# main_pll_mmr_MAIN_PLL_MMR_CFG_00680000h register map
Vendor: Texas Instruments
Peripheral module from a debugger description file (folder am62D).
Registers are 32-bit, read-write, reset values left out (the file's numbers can be read two ways) unless marked. A register's access mark holds for its fields unless they carry their own. Offsets are as the file gives them; lines under a group give offsets from that group; [hi:lo] are bit positions; {n}, {i} and the like mark numbered series; 'fields as' and 'values as' point back to an identical list; <NAME> marks a mode.

## main_pll_mmr_CFG
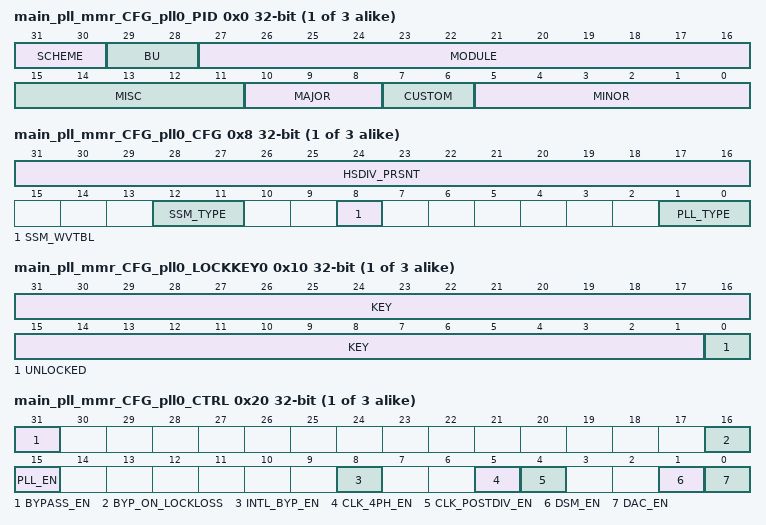
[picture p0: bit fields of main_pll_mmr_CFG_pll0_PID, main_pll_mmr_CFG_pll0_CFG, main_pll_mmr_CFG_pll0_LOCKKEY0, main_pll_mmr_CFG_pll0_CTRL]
{0x0+0x1000*i} main_pll_mmr_CFG_pll{i}_PID ro (i=0..2)
  [31:30] SCHEME — PID follows new scheme Reset Source: sys_por_arst_rst_n
  [29:28] BU — Business Unit - Processors Reset Source: sys_por_arst_rst_n
  [27:16] MODULE — Module functional identifier Reset Source: sys_por_arst_rst_n
  [15:11] MISC — Misc revision number Reset Source: sys_por_arst_rst_n
  [10:8] MAJOR — Major revision number Reset Source: sys_por_arst_rst_n
  [7:6] CUSTOM — custom revision number Reset Source: sys_por_arst_rst_n
  [5:0] MINOR — Minor revision number Reset Source: sys_por_arst_rst_n
{0x8+0x1000*i} main_pll_mmr_CFG_pll{i}_CFG ro (i=0..2)
  [31:16] HSDIV_PRSNT — High Speed Divider Presence Each bit Indicates the presence of High Speed dividers 0-15. By definition HSDIV[4:0] are connected the PLL FOUTVCO output clock and HSDIV[15:5] areconnected to the PLL FOUTPOSTDIV output clock Reset Source: sys_por_arst_rst_n
  [12:11] SSM_TYPE — Spread spectrum module presence Field values (Others are reserved): 2'b00 - SSM is not present 2'b01 - SSM is present 2'b10 - Reserved 2'b11 - Reserved Reset Source: sys_por_arst_rst_n
  [8] SSM_WVTBL — Spread spectrum wave table presence 1'b0 - SSM Wave table is not present 1'b1 - SSM Wave table is present Reset Source: sys_por_arst_rst_n
  [1:0] PLL_TYPE — Indicates PLL type Field values (Others are reserved): 2'b00 - Fractional PLL 2'b01 - FractionalF PLL 2'b10 - De-Skew PLL Reset Source: sys_por_arst_rst_n
{0x10+0x1000*i} main_pll_mmr_CFG_pll{i}_LOCKKEY0 access per field (i=0..2)
  [31:1] KEY rw — Write the kick0 unlock value followed by the kick1 unlock value to unlock the write-protectedPartition{i} registers Reset Source: srst_n
  [0] UNLOCKED ro — Unlock status. When set, indicates that the proper unlock sequence has been performed and the partition isunlocked for Writing. Reset Source: srst_n
{0x14+0x1000*i} main_pll_mmr_CFG_pll{i}_LOCKKEY1 (i=0..2)
  [31:0] LOCKKEY1_VAL — Write the kick1 unlock value after the kick0 unlock value to unlock the write-protected Partition{i}registers Reset Source: srst_n
{0x20+0x1000*i} main_pll_mmr_CFG_pll{i}_CTRL (i=0..2)
  [31] BYPASS_EN — Bypass enable. This controls the glitch-free bypass mux. The bypass_en bit should be set prior tomaking any changes to the PLL settings. 1'b0 - Synchronously select PLL and associated HSDIV clock outputs 1'b1 - Synchronously select the reference clock for all PLL and HSDIV clock outputs Reset Source: sys_por_arst_rst_n
  [16] BYP_ON_LOCKLOSS — Bypass on loss of PLL lock. This bit controls the PLL bypass mux to automatically switch theclock source to the reference clock when the PLL losses lock. 1'b0 - Do not automatically switch to ref clock source on PLL lock loss 1'b1 - Switch to ref clock source when PLL losses lock Reset Source: sys_por_arst_rst_n
  [15] PLL_EN — PLL enable 1'b0 - PLL is disabled 1'b1 - PLL is enabled Reset Source: sys_por_arst_rst_n
  [8] INTL_BYP_EN — PLL internal bypass enable. This is an asynchronous mux which can produce glitches on the outputclocks during switching. 1'b0 - Output clocks are derived from the VCO clock 1'b1 - Output clocks are derived from the FREF reference clock Reset Source: sys_por_arst_rst_n
  [5] CLK_4PH_EN — Enable 4-phase clock generator. This bit is ignored if clk_postdiv_en=0 1'b0 - 4-phase dividers disabled. FOUT1PHx and FOUTn clocks are held low. 1'b1 - 4-phase dividers enabled. FOUT1PH0/90/180/270 and FOUT2, FOUT3, FOUT4 clocks are enabled. Reset Source: sys_por_arst_rst_n
  [4] CLK_POSTDIV_EN — Post divide CLK enable 1'b0 - Post divide powered down. FOUTPOSTDIV and all auxiliary PLL clocks (4-ohase andsynchronous divided clocks) are held low 1'b1 - Post divide enabled. FOUTPOSTDIV, 4-phase and synchronous clocks are enabled. Reset Source: sys_por_arst_rst_n
  [1] DSM_EN — Delta-Sigma modulator enable 1'b0 - Delta-Sigma modulator is disabled (use integer divide mode) 1'b1 - Delta-Sigma modulator is enabled (use fractional divide mode) Reset Source: sys_por_arst_rst_n
  [0] DAC_EN — Enable fractional noise canceling DACThis bit has no function (DAC is always disabled) in integer divide mode (when dsm_en=0) 1'b0 - Fractional NC DAC is disabled (for Test modes only) 1'b1 - Fractional NC DAC is enabled (ignored in integer divide mode) Reset Source: sys_por_arst_rst_n
{0x24+0x1000*i} main_pll_mmr_CFG_pll{i}_STAT ro (i=0..2)
  [0] LOCK — PLL lock status. Software should wait for lock to be asserted before clearing thePLL_CTRL_bypass_en bit 1'b0 - PLL is not locked 1'b1 - PLL is locked Reset Source: sys_por_arst_rst_n
{0x30+0x1000*i} main_pll_mmr_CFG_pll{i}_FREQ_CTRL0 (i=0..2)
  [11:0] FB_DIV_INT — PLL feedback divider (integer portion) In Integer mode values of 16 - 3200 (dec) are supported. In Fractional mode values of 20 to 320 are supported. 12'h010 - Divide by 16 12'h011 - Divide by 17 : 12'h140 - Divide by 320 : 12'hC80 - Divide by 3200 12'hC81 - 12'hFFF - Not supported Reset Source: sys_por_arst_rst_n
{0x34+0x1000*i} main_pll_mmr_CFG_pll{i}_FREQ_CTRL1 (i=0..2)
  [23:0] FB_DIV_FRAC — PLL feedback divider (fractional portion) Supports values of 0 to 0.999999940395. The total feedback divide value is (fb_div_int + fb_div_frac / (2^24)) 24'h000000 - 0 24'h000001 - .000000059605 (1/(2^24)) 24'h000002 - .000000119209 (2/(2^24)) : 24'h800000 - .500000000000 : 24'hFFFFFF - .999999940395 (1677215/(2^24)) Reset Source: sys_por_arst_rst_n
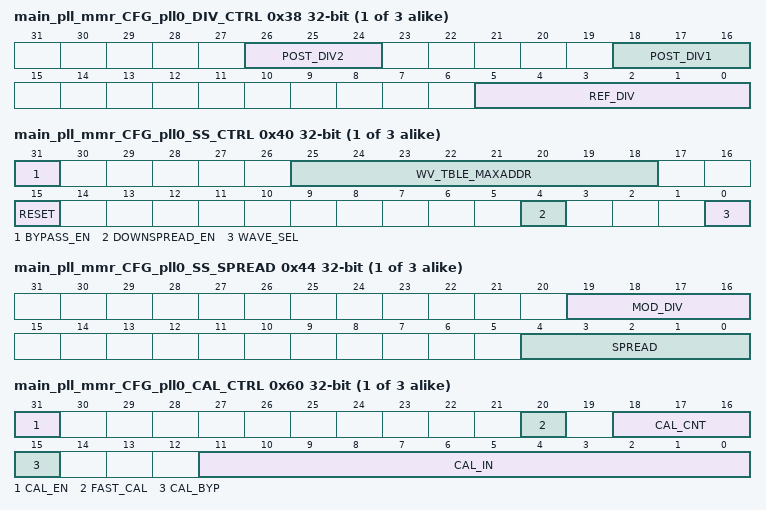
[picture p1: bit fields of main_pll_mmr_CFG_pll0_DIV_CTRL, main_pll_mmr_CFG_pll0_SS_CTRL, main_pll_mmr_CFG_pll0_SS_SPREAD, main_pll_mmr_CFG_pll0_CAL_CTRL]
{0x38+0x1000*i} main_pll_mmr_CFG_pll{i}_DIV_CTRL (i=0..2)
  [26:24] POST_DIV2 — Secondary post divider. Supports values of 1-7 Reset Source: sys_por_arst_rst_n
  [18:16] POST_DIV1 — Primary post divider. To ensure correct operation, post_div1 must always be programmed to avalue equal to or greater that post_div2. Supports values of 1-7i Field values (Others are reserved): 3'b000 - Reserved (do not use) 3'b001 - Divide by 1 3'b010 - Divide by 2 3'b011 - Divide by 3 3'b100 - Divide by 4 3'b101 - Divide by 5 3'b110 - Divide by 6 3'b111 - Divide by 7 Reset Source: sys_por_arst_rst_n
  [5:0] REF_DIV — Reference clock pre-divider. Supports values of 1-63 6'b000000 - Reserved /(do not use/) 6'b000001 - Divide by 1 6'b000010 - Divide by 2 : 6'b111111 - Divide by 63 Reset Source: sys_por_arst_rst_n
{0x40+0x1000*i} main_pll_mmr_CFG_pll{i}_SS_CTRL (i=0..2)
  [31] BYPASS_EN — Bypass the SS modulator.1'b0 - Spread spectrum modulation is enabled1'b1 - SSMOD is bypassed. No modulation of PLL frequency Reset Source: sys_por_arst_rst_n
  [25:18] WV_TBLE_MAXADDR — Wave table max address. Indicates the maximum number of address bits used to access the external wave table. These bits are not used if PLL_CFG_ssm_wvtbl = 0 Reset Source: sys_por_arst_rst_n
  [15] RESET — SSM reset. When set to 1 the SSM modulator is in reset Reset Source: sys_por_arst_rst_n
  [4] DOWNSPREAD_EN — Selects center spread or down spread clock variance1'b0 - Center spread1'b1 - Down spread Reset Source: sys_por_arst_rst_n
  [0] WAVE_SEL — Wave pattern select External wave table should only be selected if PLL_CFG_ssm_wvtbl = 1Field values (Others are reserved):1'b0 - Use 128 point triangle wave table1'b1 - Use external wave table Reset Source: sys_por_arst_rst_n
{0x44+0x1000*i} main_pll_mmr_CFG_pll{i}_SS_SPREAD (i=0..2)
  [19:16] MOD_DIV — Input clock divider. This divider sets the modulation frequency. Supports divide values of 1-15 Reset Source: sys_por_arst_rst_n
  [4:0] SPREAD — Sets the spread modulation depth. The depth is spread*0.1%5'b00000 - Reserved (don't use)5'b00001 - 0.1%5'b00010 - 0.2%:5'b10000 - 1.6%:5'b11111 - 3.1% Reset Source: sys_por_arst_rst_n
{0x60+0x1000*i} main_pll_mmr_CFG_pll{i}_CAL_CTRL (i=0..2)
  [31] CAL_EN — Calibration enable to actively adjust for input skew 1'b0 - Disabled. Static phase offset determined by analog matching only 1'b1 - Enabled. Static phase offset adjusted by phase sensing at input Reset Source: sys_por_arst_rst_n
  [20] FAST_CAL — Fast calibration enabled 1'b0 - Normal operation 1'b1 - Used for initial calibration if initial value is not already known Reset Source: sys_por_arst_rst_n
  [18:16] CAL_CNT — Calibration loop programmable counter. Selects the number of PFD edges to wait after eachcalibration step defined by 2**cal_cnt Reset Source: sys_por_arst_rst_n
  [15] CAL_BYP — Calibration bypass 1'b0 - Use the calibration output to set the phase correction 1'b1 - Use the cal_in input value to set the phase correction Reset Source: sys_por_arst_rst_n
  [11:0] CAL_IN — Calibration input When cal_byp is 1'b0, this represents the initial condition for calibration. When cal_byp is 1'b1, this is the override value for calibration. Value is a signed integer with positive values delaying the faster path reset and negative valuesdelaying the slower path reset. Reset Source: sys_por_arst_rst_n
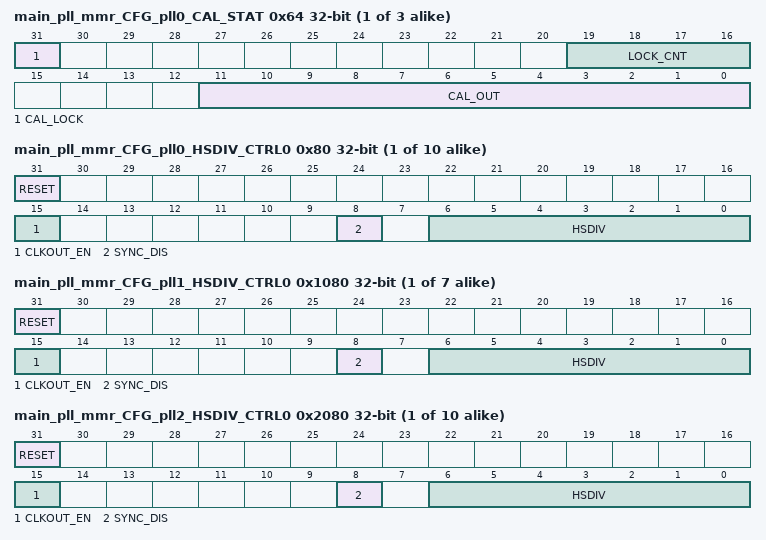
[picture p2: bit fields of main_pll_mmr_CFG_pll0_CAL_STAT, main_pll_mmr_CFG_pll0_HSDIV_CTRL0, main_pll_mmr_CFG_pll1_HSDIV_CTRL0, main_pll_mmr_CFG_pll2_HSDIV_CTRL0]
{0x64+0x1000*i} main_pll_mmr_CFG_pll{i}_CAL_STAT ro (i=0..2)
  [31] CAL_LOCK — Reserved for future use Reset Source: sys_por_arst_rst_n
  [19:16] LOCK_CNT — Reserved for future use Reset Source: sys_por_arst_rst_n
  [11:0] CAL_OUT — Output of the calibration block if cal_byp = 1'b0. If cal_byp = 1'b1 it is a buffer version of cal_in[11:0]. Can be used to read the phase calibration state to for later use as an override value to bypass skew calibration Reset Source: sys_por_arst_rst_n
{0x80+4i} main_pll_mmr_CFG_pll0_HSDIV_CTRL{i} (i=0..9)
  [31] RESET — SSM reset. When set to 1 the SSM modulator is in resetl Reset Source: sys_por_arst_rst_n
  [15] CLKOUT_EN — CLKOUT1 enable1'b0 - Synchronously disable CLKOUT11'b1 - Synchronously enable CLKOUT1 Reset Source: sys_por_arst_rst_n
  [8] SYNC_DIS — Disable divider synchronization logic0 - Changes to DIV value synchronized to prevent glitches1 - Changes are asynchronous Reset Source: sys_por_arst_rst_n
  [6:0] HSDIV — CLKOUT0 divider value (HSDIV1+1)Allowed values are 0-127 Reset Source: sys_por_arst_rst_n
{0x1080+4i} main_pll_mmr_CFG_pll1_HSDIV_CTRL{i} (i=0..6)
  fields as main_pll_mmr_CFG_pll0_HSDIV_CTRL0
{0x2080+4i} main_pll_mmr_CFG_pll2_HSDIV_CTRL{i} (i=0..9)
  fields as main_pll_mmr_CFG_pll0_HSDIV_CTRL0
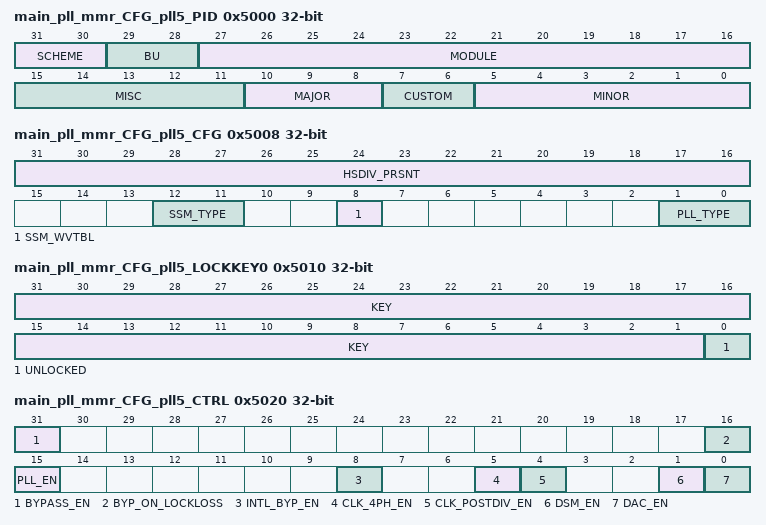
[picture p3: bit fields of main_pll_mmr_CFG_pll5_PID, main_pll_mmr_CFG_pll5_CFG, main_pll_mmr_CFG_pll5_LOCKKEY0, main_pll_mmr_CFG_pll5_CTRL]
0x5000 main_pll_mmr_CFG_pll5_PID ro
  fields as main_pll_mmr_CFG_pll0_PID
0x5008 main_pll_mmr_CFG_pll5_CFG ro
  fields as main_pll_mmr_CFG_pll0_CFG
0x5010 main_pll_mmr_CFG_pll5_LOCKKEY0 access per field
  [31:1] KEY rw — Write the kick0 unlock value followed by the kick1 unlock value to unlock the write-protectedPartition5 registers Reset Source: srst_n
  [0] UNLOCKED ro — Unlock status. When set, indicates that the proper unlock sequence has been performed and the partition isunlocked for Writing. Reset Source: srst_n
0x5014 main_pll_mmr_CFG_pll5_LOCKKEY1
  [31:0] LOCKKEY1_VAL — Write the kick1 unlock value after the kick0 unlock value to unlock the write-protected Partition5registers Reset Source: srst_n
0x5020 main_pll_mmr_CFG_pll5_CTRL
  fields as main_pll_mmr_CFG_pll0_CTRL
0x5024 main_pll_mmr_CFG_pll5_STAT ro
  fields as main_pll_mmr_CFG_pll0_STAT
0x5030 main_pll_mmr_CFG_pll5_FREQ_CTRL0
  fields as main_pll_mmr_CFG_pll0_FREQ_CTRL0
0x5034 main_pll_mmr_CFG_pll5_FREQ_CTRL1
  fields as main_pll_mmr_CFG_pll0_FREQ_CTRL1
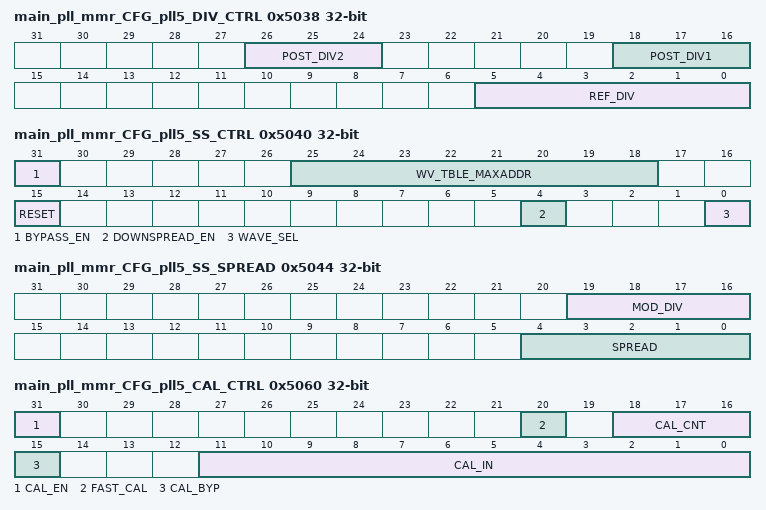
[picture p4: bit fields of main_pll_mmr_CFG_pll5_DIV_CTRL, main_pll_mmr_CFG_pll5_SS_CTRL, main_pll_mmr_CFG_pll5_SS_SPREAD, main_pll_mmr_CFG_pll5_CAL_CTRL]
0x5038 main_pll_mmr_CFG_pll5_DIV_CTRL
  fields as main_pll_mmr_CFG_pll0_DIV_CTRL
0x5040 main_pll_mmr_CFG_pll5_SS_CTRL
  fields as main_pll_mmr_CFG_pll0_SS_CTRL
0x5044 main_pll_mmr_CFG_pll5_SS_SPREAD
  fields as main_pll_mmr_CFG_pll0_SS_SPREAD
0x5060 main_pll_mmr_CFG_pll5_CAL_CTRL
  fields as main_pll_mmr_CFG_pll0_CAL_CTRL
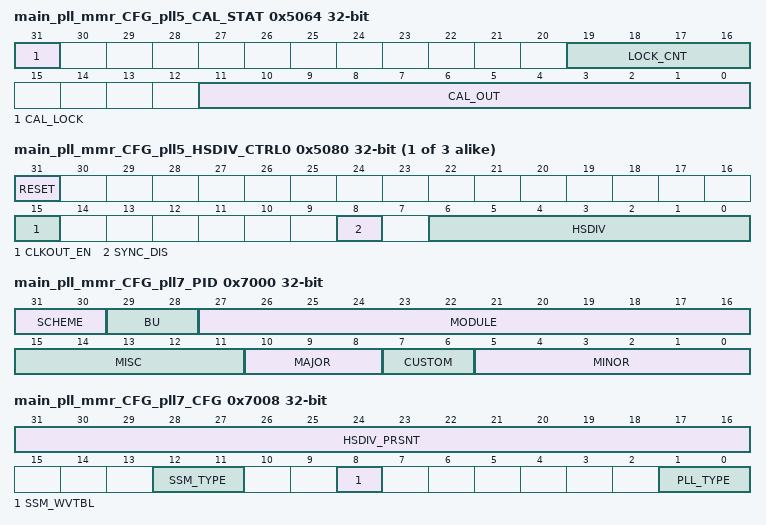
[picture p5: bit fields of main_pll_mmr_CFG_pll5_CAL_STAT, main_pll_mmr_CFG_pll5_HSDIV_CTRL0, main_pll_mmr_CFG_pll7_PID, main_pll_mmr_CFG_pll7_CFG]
0x5064 main_pll_mmr_CFG_pll5_CAL_STAT ro
  fields as main_pll_mmr_CFG_pll0_CAL_STAT
{0x5080+4i} main_pll_mmr_CFG_pll5_HSDIV_CTRL{i} (i=0..2)
  fields as main_pll_mmr_CFG_pll0_HSDIV_CTRL0
0x7000 main_pll_mmr_CFG_pll7_PID ro
  fields as main_pll_mmr_CFG_pll0_PID
0x7008 main_pll_mmr_CFG_pll7_CFG ro
  fields as main_pll_mmr_CFG_pll0_CFG
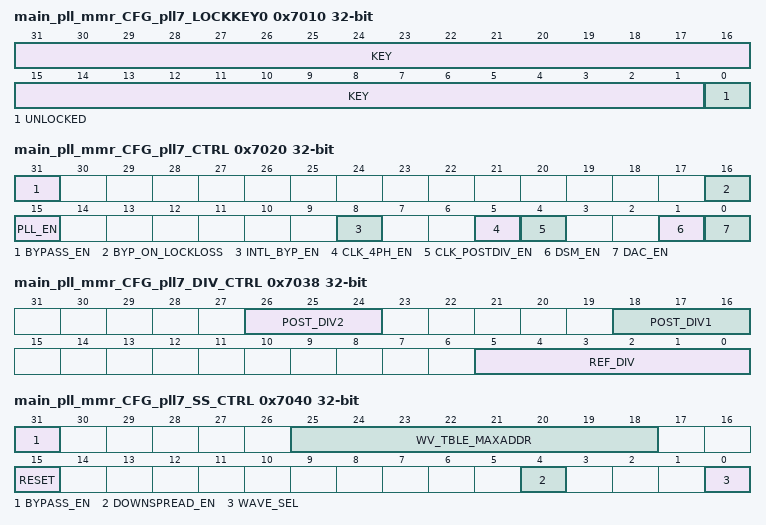
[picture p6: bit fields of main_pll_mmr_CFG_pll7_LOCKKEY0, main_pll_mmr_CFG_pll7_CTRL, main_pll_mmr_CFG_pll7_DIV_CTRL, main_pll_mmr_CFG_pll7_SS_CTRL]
0x7010 main_pll_mmr_CFG_pll7_LOCKKEY0 access per field
  [31:1] KEY rw — Write the kick0 unlock value followed by the kick1 unlock value to unlock the write-protectedPartition7 registers Reset Source: srst_n
  [0] UNLOCKED ro — Unlock status. When set, indicates that the proper unlock sequence has been performed and the partition isunlocked for Writing. Reset Source: srst_n
0x7014 main_pll_mmr_CFG_pll7_LOCKKEY1
  [31:0] LOCKKEY1_VAL — Write the kick1 unlock value after the kick0 unlock value to unlock the write-protected Partition7registers Reset Source: srst_n
0x7020 main_pll_mmr_CFG_pll7_CTRL
  fields as main_pll_mmr_CFG_pll0_CTRL
0x7024 main_pll_mmr_CFG_pll7_STAT ro
  fields as main_pll_mmr_CFG_pll0_STAT
0x7030 main_pll_mmr_CFG_pll7_FREQ_CTRL0
  fields as main_pll_mmr_CFG_pll0_FREQ_CTRL0
0x7034 main_pll_mmr_CFG_pll7_FREQ_CTRL1
  fields as main_pll_mmr_CFG_pll0_FREQ_CTRL1
0x7038 main_pll_mmr_CFG_pll7_DIV_CTRL
  fields as main_pll_mmr_CFG_pll0_DIV_CTRL
0x7040 main_pll_mmr_CFG_pll7_SS_CTRL
  fields as main_pll_mmr_CFG_pll0_SS_CTRL
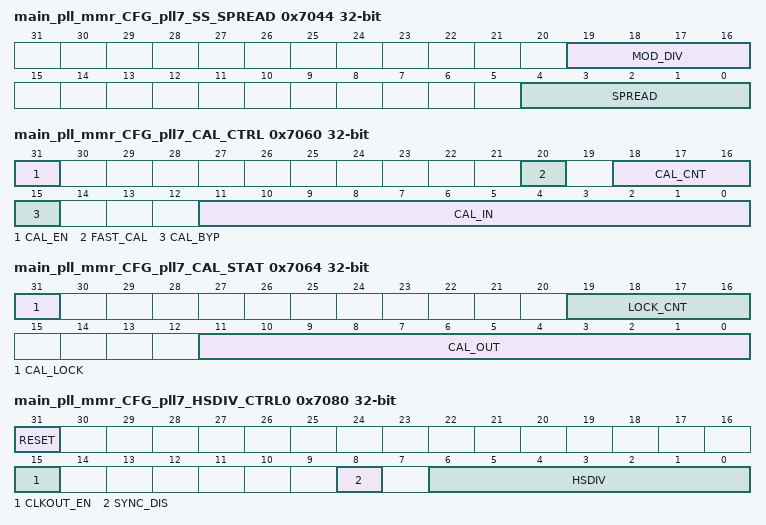
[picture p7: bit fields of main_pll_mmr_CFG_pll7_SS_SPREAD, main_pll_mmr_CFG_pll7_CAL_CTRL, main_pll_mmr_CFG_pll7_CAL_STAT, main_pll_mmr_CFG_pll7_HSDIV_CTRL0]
0x7044 main_pll_mmr_CFG_pll7_SS_SPREAD
  fields as main_pll_mmr_CFG_pll0_SS_SPREAD
0x7060 main_pll_mmr_CFG_pll7_CAL_CTRL
  fields as main_pll_mmr_CFG_pll0_CAL_CTRL
0x7064 main_pll_mmr_CFG_pll7_CAL_STAT ro
  fields as main_pll_mmr_CFG_pll0_CAL_STAT
0x7080 main_pll_mmr_CFG_pll7_HSDIV_CTRL0
  fields as main_pll_mmr_CFG_pll0_HSDIV_CTRL0
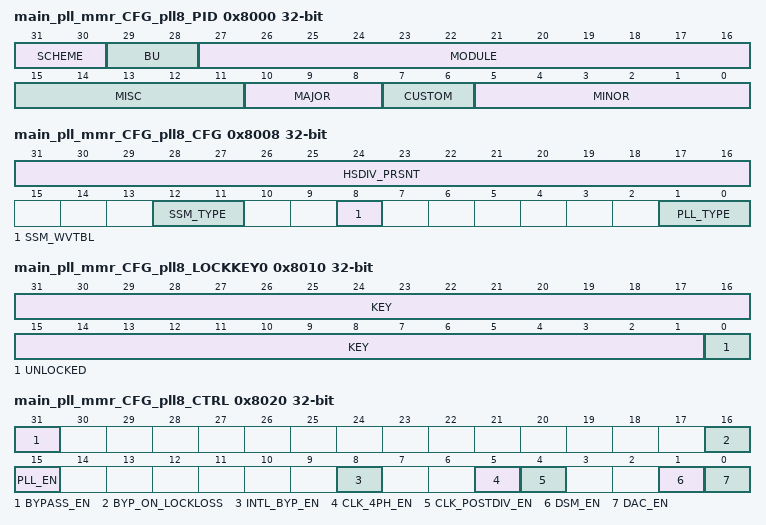
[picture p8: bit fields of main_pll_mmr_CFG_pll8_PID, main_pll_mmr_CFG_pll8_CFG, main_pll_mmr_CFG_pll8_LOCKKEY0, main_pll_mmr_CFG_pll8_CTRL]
0x8000 main_pll_mmr_CFG_pll8_PID ro
  fields as main_pll_mmr_CFG_pll0_PID
0x8008 main_pll_mmr_CFG_pll8_CFG ro
  fields as main_pll_mmr_CFG_pll0_CFG
0x8010 main_pll_mmr_CFG_pll8_LOCKKEY0 access per field
  [31:1] KEY rw — Write the kick0 unlock value followed by the kick1 unlock value to unlock the write-protectedPartition8 registers Reset Source: srst_n
  [0] UNLOCKED ro — Unlock status. When set, indicates that the proper unlock sequence has been performed and the partition isunlocked for Writing. Reset Source: srst_n
0x8014 main_pll_mmr_CFG_pll8_LOCKKEY1
  [31:0] LOCKKEY1_VAL — Write the kick1 unlock value after the kick0 unlock value to unlock the write-protected Partition8registers Reset Source: srst_n
0x8020 main_pll_mmr_CFG_pll8_CTRL
  fields as main_pll_mmr_CFG_pll0_CTRL
0x8024 main_pll_mmr_CFG_pll8_STAT ro
  fields as main_pll_mmr_CFG_pll0_STAT
0x8030 main_pll_mmr_CFG_pll8_FREQ_CTRL0
  fields as main_pll_mmr_CFG_pll0_FREQ_CTRL0
0x8034 main_pll_mmr_CFG_pll8_FREQ_CTRL1
  fields as main_pll_mmr_CFG_pll0_FREQ_CTRL1
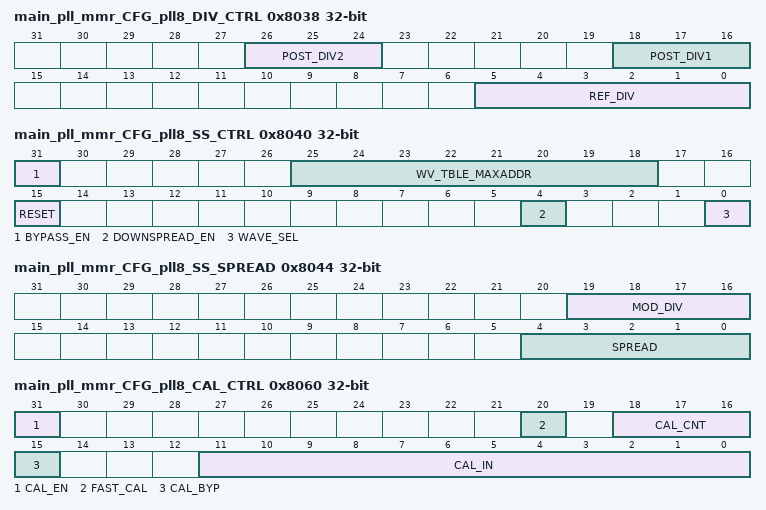
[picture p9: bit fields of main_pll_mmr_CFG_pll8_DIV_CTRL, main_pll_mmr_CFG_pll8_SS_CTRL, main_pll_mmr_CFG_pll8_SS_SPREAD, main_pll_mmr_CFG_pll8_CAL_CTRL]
0x8038 main_pll_mmr_CFG_pll8_DIV_CTRL
  fields as main_pll_mmr_CFG_pll0_DIV_CTRL
0x8040 main_pll_mmr_CFG_pll8_SS_CTRL
  fields as main_pll_mmr_CFG_pll0_SS_CTRL
0x8044 main_pll_mmr_CFG_pll8_SS_SPREAD
  fields as main_pll_mmr_CFG_pll0_SS_SPREAD
0x8060 main_pll_mmr_CFG_pll8_CAL_CTRL
  fields as main_pll_mmr_CFG_pll0_CAL_CTRL
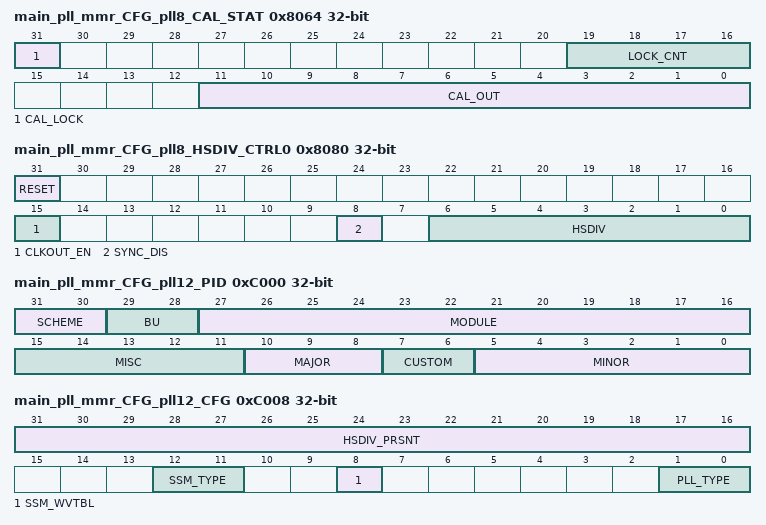
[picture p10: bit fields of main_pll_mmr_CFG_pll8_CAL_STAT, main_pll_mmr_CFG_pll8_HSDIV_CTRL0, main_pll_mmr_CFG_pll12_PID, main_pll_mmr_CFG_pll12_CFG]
0x8064 main_pll_mmr_CFG_pll8_CAL_STAT ro
  fields as main_pll_mmr_CFG_pll0_CAL_STAT
0x8080 main_pll_mmr_CFG_pll8_HSDIV_CTRL0
  fields as main_pll_mmr_CFG_pll0_HSDIV_CTRL0
0xC000 main_pll_mmr_CFG_pll12_PID ro
  fields as main_pll_mmr_CFG_pll0_PID
0xC008 main_pll_mmr_CFG_pll12_CFG ro
  fields as main_pll_mmr_CFG_pll0_CFG
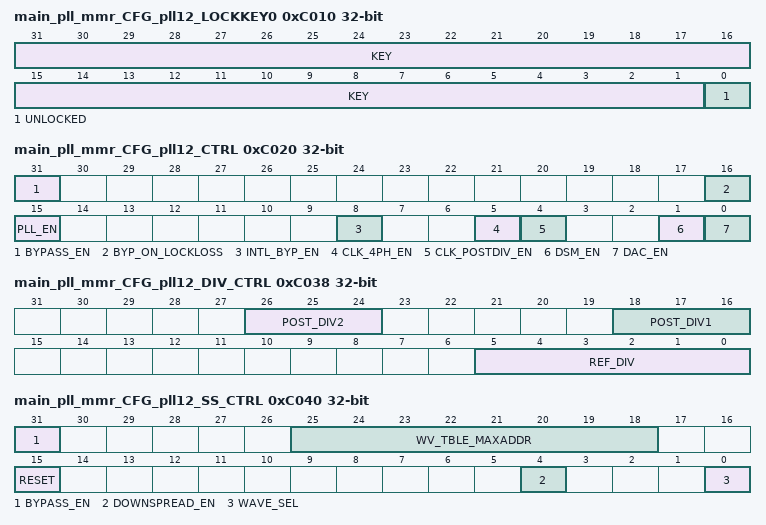
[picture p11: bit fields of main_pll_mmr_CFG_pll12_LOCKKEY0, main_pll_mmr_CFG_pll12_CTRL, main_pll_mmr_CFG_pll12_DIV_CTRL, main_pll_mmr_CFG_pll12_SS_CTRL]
0xC010 main_pll_mmr_CFG_pll12_LOCKKEY0 access per field
  [31:1] KEY rw — Write the kick0 unlock value followed by the kick1 unlock value to unlock the write-protectedPartition12 registers Reset Source: srst_n
  [0] UNLOCKED ro — Unlock status. When set, indicates that the proper unlock sequence has been performed and the partition isunlocked for Writing. Reset Source: srst_n
0xC014 main_pll_mmr_CFG_pll12_LOCKKEY1
  [31:0] LOCKKEY1_VAL — Write the kick1 unlock value after the kick0 unlock value to unlock the write-protected Partition12registers Reset Source: srst_n
0xC020 main_pll_mmr_CFG_pll12_CTRL
  fields as main_pll_mmr_CFG_pll0_CTRL
0xC024 main_pll_mmr_CFG_pll12_STAT ro
  fields as main_pll_mmr_CFG_pll0_STAT
0xC030 main_pll_mmr_CFG_pll12_FREQ_CTRL0
  fields as main_pll_mmr_CFG_pll0_FREQ_CTRL0
0xC034 main_pll_mmr_CFG_pll12_FREQ_CTRL1
  fields as main_pll_mmr_CFG_pll0_FREQ_CTRL1
0xC038 main_pll_mmr_CFG_pll12_DIV_CTRL
  fields as main_pll_mmr_CFG_pll0_DIV_CTRL
0xC040 main_pll_mmr_CFG_pll12_SS_CTRL
  fields as main_pll_mmr_CFG_pll0_SS_CTRL
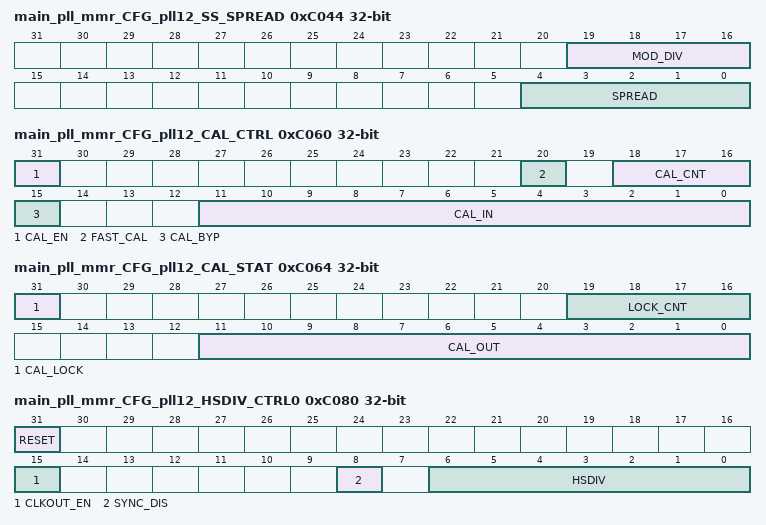
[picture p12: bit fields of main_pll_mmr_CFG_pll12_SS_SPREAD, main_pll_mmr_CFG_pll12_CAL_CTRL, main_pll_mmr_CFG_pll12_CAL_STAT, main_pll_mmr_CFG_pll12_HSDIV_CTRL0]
0xC044 main_pll_mmr_CFG_pll12_SS_SPREAD
  fields as main_pll_mmr_CFG_pll0_SS_SPREAD
0xC060 main_pll_mmr_CFG_pll12_CAL_CTRL
  fields as main_pll_mmr_CFG_pll0_CAL_CTRL
0xC064 main_pll_mmr_CFG_pll12_CAL_STAT ro
  fields as main_pll_mmr_CFG_pll0_CAL_STAT
0xC080 main_pll_mmr_CFG_pll12_HSDIV_CTRL0
  fields as main_pll_mmr_CFG_pll0_HSDIV_CTRL0
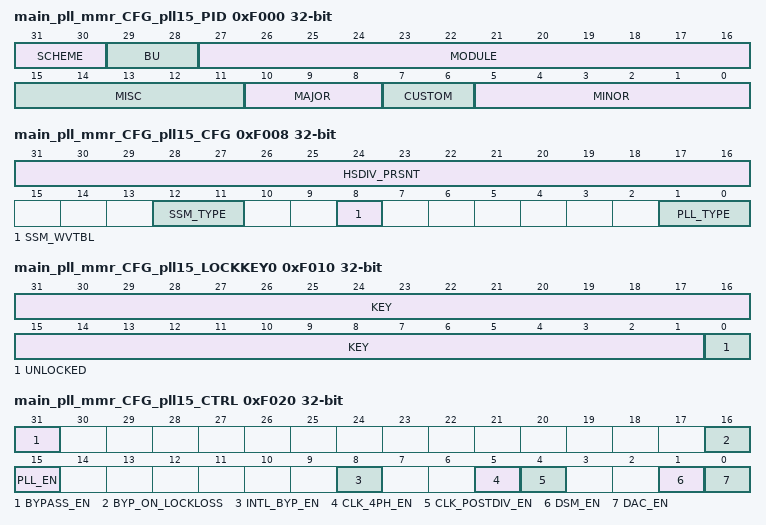
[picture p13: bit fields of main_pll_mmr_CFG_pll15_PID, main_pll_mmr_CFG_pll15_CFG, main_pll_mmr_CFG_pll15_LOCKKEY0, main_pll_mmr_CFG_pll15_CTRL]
0xF000 main_pll_mmr_CFG_pll15_PID ro
  fields as main_pll_mmr_CFG_pll0_PID
0xF008 main_pll_mmr_CFG_pll15_CFG ro
  fields as main_pll_mmr_CFG_pll0_CFG
0xF010 main_pll_mmr_CFG_pll15_LOCKKEY0 access per field
  [31:1] KEY rw — Write the kick0 unlock value followed by the kick1 unlock value to unlock the write-protectedPartition15 registers Reset Source: srst_n
  [0] UNLOCKED ro — Unlock status. When set, indicates that the proper unlock sequence has been performed and the partition isunlocked for Writing. Reset Source: srst_n
0xF014 main_pll_mmr_CFG_pll15_LOCKKEY1
  [31:0] LOCKKEY1_VAL — Write the kick1 unlock value after the kick0 unlock value to unlock the write-protected Partition15registers Reset Source: srst_n
0xF020 main_pll_mmr_CFG_pll15_CTRL
  fields as main_pll_mmr_CFG_pll0_CTRL
0xF024 main_pll_mmr_CFG_pll15_STAT ro
  fields as main_pll_mmr_CFG_pll0_STAT
0xF030 main_pll_mmr_CFG_pll15_FREQ_CTRL0
  fields as main_pll_mmr_CFG_pll0_FREQ_CTRL0
0xF034 main_pll_mmr_CFG_pll15_FREQ_CTRL1
  fields as main_pll_mmr_CFG_pll0_FREQ_CTRL1
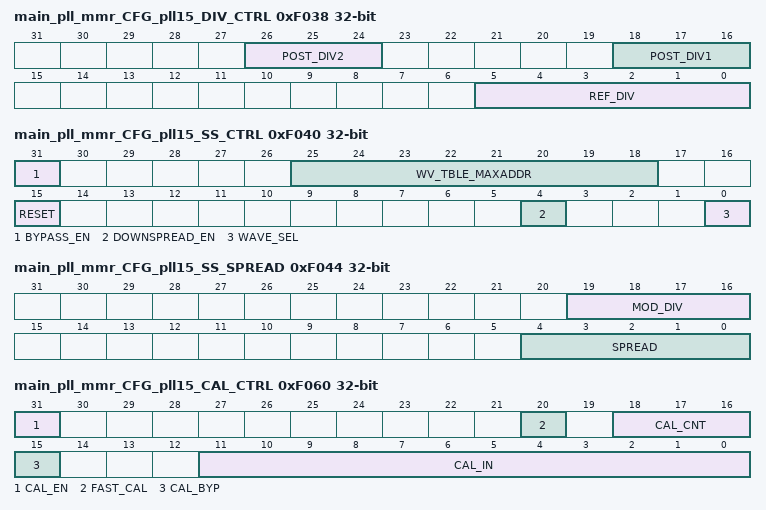
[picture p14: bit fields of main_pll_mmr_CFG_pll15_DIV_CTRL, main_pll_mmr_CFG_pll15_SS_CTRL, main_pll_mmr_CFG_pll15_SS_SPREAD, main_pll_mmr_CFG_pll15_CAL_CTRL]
0xF038 main_pll_mmr_CFG_pll15_DIV_CTRL
  fields as main_pll_mmr_CFG_pll0_DIV_CTRL
0xF040 main_pll_mmr_CFG_pll15_SS_CTRL
  fields as main_pll_mmr_CFG_pll0_SS_CTRL
0xF044 main_pll_mmr_CFG_pll15_SS_SPREAD
  fields as main_pll_mmr_CFG_pll0_SS_SPREAD
0xF060 main_pll_mmr_CFG_pll15_CAL_CTRL
  fields as main_pll_mmr_CFG_pll0_CAL_CTRL
0xF064 main_pll_mmr_CFG_pll15_CAL_STAT ro
  fields as main_pll_mmr_CFG_pll0_CAL_STAT
{0xF080+4i} main_pll_mmr_CFG_pll15_HSDIV_CTRL{i} (i=0..2)
  fields as main_pll_mmr_CFG_pll0_HSDIV_CTRL0
0x11000 main_pll_mmr_CFG_pll17_PID ro
  fields as main_pll_mmr_CFG_pll0_PID
0x11008 main_pll_mmr_CFG_pll17_CFG ro
  fields as main_pll_mmr_CFG_pll0_CFG
0x11010 main_pll_mmr_CFG_pll17_LOCKKEY0 access per field
  [31:1] KEY rw — Write the kick0 unlock value followed by the kick1 unlock value to unlock the write-protectedPartition17 registers Reset Source: srst_n
  [0] UNLOCKED ro — Unlock status. When set, indicates that the proper unlock sequence has been performed and the partition isunlocked for Writing. Reset Source: srst_n
0x11014 main_pll_mmr_CFG_pll17_LOCKKEY1
  [31:0] LOCKKEY1_VAL — Write the kick1 unlock value after the kick0 unlock value to unlock the write-protected Partition17registers Reset Source: srst_n
0x11020 main_pll_mmr_CFG_pll17_CTRL
  fields as main_pll_mmr_CFG_pll0_CTRL
0x11024 main_pll_mmr_CFG_pll17_STAT ro
  fields as main_pll_mmr_CFG_pll0_STAT
0x11030 main_pll_mmr_CFG_pll17_FREQ_CTRL0
  fields as main_pll_mmr_CFG_pll0_FREQ_CTRL0
0x11034 main_pll_mmr_CFG_pll17_FREQ_CTRL1
  fields as main_pll_mmr_CFG_pll0_FREQ_CTRL1
0x11038 main_pll_mmr_CFG_pll17_DIV_CTRL
  fields as main_pll_mmr_CFG_pll0_DIV_CTRL
0x11040 main_pll_mmr_CFG_pll17_SS_CTRL
  fields as main_pll_mmr_CFG_pll0_SS_CTRL
0x11044 main_pll_mmr_CFG_pll17_SS_SPREAD
  fields as main_pll_mmr_CFG_pll0_SS_SPREAD
0x11060 main_pll_mmr_CFG_pll17_CAL_CTRL
  fields as main_pll_mmr_CFG_pll0_CAL_CTRL
0x11064 main_pll_mmr_CFG_pll17_CAL_STAT ro
  fields as main_pll_mmr_CFG_pll0_CAL_STAT
0x11080 main_pll_mmr_CFG_pll17_HSDIV_CTRL0
  fields as main_pll_mmr_CFG_pll0_HSDIV_CTRL0
